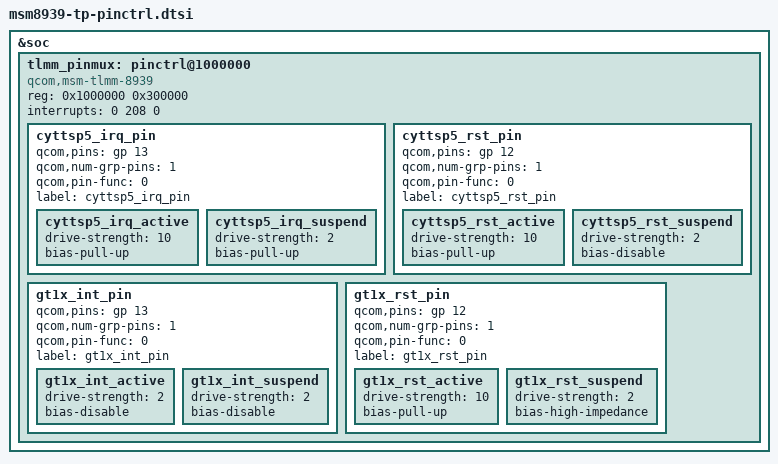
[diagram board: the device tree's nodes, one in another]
/* Copyright (c) 2013-2014, The Linux Foundation. All rights reserved.
 *
 * This program is free software; you can redistribute it and/or modify
 * it under the terms of the GNU General Public License version 2 and
 * only version 2 as published by the Free Software Foundation.
 *
 * This program is distributed in the hope that it will be useful,
 * but WITHOUT ANY WARRANTY; without even the implied warranty of
 * MERCHANTABILITY or FITNESS FOR A PARTICULAR PURPOSE.  See the
 * GNU General Public License for more details.
 */

&soc {
	tlmm_pinmux: pinctrl@1000000 {
		compatible = "qcom,msm-tlmm-8939", "qcom,msm-tlmm-8916";
		reg = <0x1000000 0x300000>;
		interrupts = <0 208 0>;

		cyttsp5_irq_pin {
			qcom,pins = <&gp 13>;
			qcom,num-grp-pins = <1>;
			qcom,pin-func = <0>;
			label = "cyttsp5_irq_pin";

			cyttsp5_irq_active: cyttsp5_irq_active {
				drive-strength = <10>;
				bias-pull-up;
			};

			cyttsp5_irq_suspend: cyttsp5_irq_suspend {
				drive-strength = <2>;
				bias-pull-up;
			};
		};
		cyttsp5_rst_pin {
			qcom,pins = <&gp 12>;
			qcom,num-grp-pins = <1>;
			qcom,pin-func = <0>;
			label = "cyttsp5_rst_pin";

			cyttsp5_rst_active: cyttsp5_rst_active {
				drive-strength = <10>;
				bias-pull-up;
			};

			cyttsp5_rst_suspend: cyttsp5_rst_suspend {
				drive-strength = <2>;
				bias-disable;
			};
		};
		
		gt1x_int_pin {
			qcom,pins = <&gp 13>;
			qcom,num-grp-pins = <1>;
			qcom,pin-func = <0>;
			label = "gt1x_int_pin";
			/*active state*/
			gt1x_int_active: gt1x_int_active {
				drive-strength = <2>;/*2MA*/
				bias-disable;
			};
			/*suspended state*/
			gt1x_int_suspend: gt1x_int_suspend {
				drive-strength = <2>;/*2MA*/
				bias-disable;
			};
		};

		gt1x_rst_pin {
			qcom,pins = <&gp 12>;
			qcom,num-grp-pins = <1>;
			qcom,pin-func = <0>;
			label = "gt1x_rst_pin";

			gt1x_rst_active: gt1x_rst_active {
				drive-strength = <10>;
				bias-pull-up;
			};

			gt1x_rst_suspend: gt1x_rst_suspend {
				drive-strength = <2>;
				bias-high-impedance;
			};
		};

	};
};


